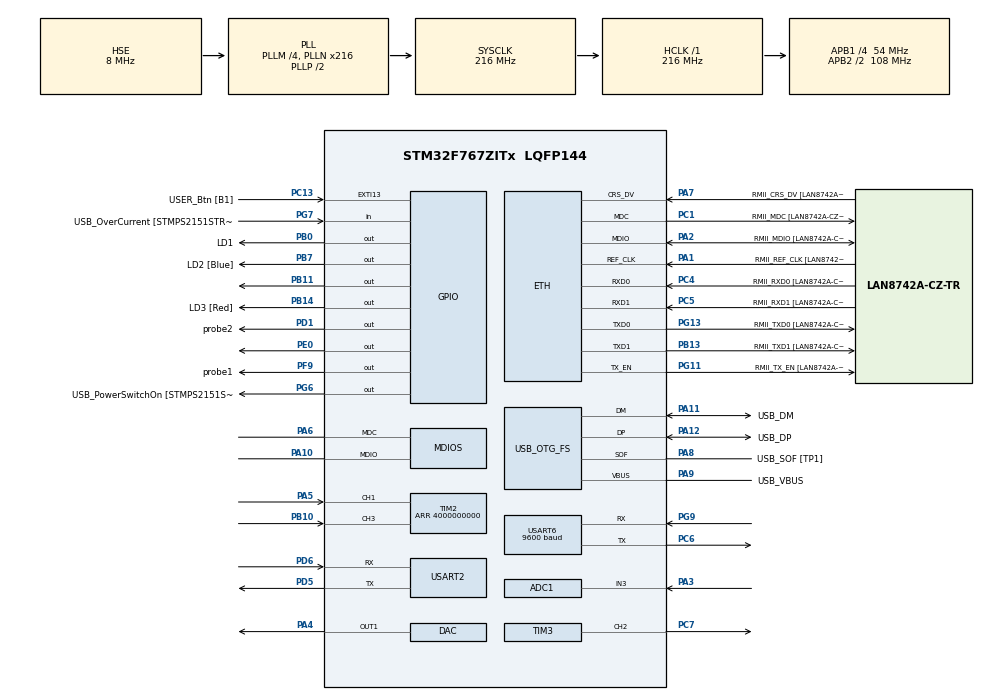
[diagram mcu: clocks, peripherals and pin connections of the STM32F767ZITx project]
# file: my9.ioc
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ADC1.Channel-6\#ChannelRegularConversion=ADC_CHANNEL_3
ADC1.ClockPrescaler=ADC_CLOCK_SYNC_PCLK_DIV4
ADC1.ContinuousConvMode=ENABLE
ADC1.DMAAccessMode=ADC_DMAACCESSMODE_2
ADC1.DMAContinuousRequests=ENABLE
ADC1.DataAlign=ADC_DATAALIGN_RIGHT
ADC1.DiscontinuousConvMode=DISABLE
ADC1.EOCSelection=ADC_EOC_SEQ_CONV
ADC1.EnableAnalogWatchDog=false
ADC1.ExternalTrigConv=ADC_SOFTWARE_START
ADC1.ExternalTrigConvEdge=ADC_EXTERNALTRIGCONVEDGE_NONE
ADC1.InjNumberOfConversion=0
ADC1.Mode=ADC_TRIPLEMODE_INTERL
ADC1.NbrOfConversion=1
ADC1.NbrOfConversionFlag=1
ADC1.Rank-6\#ChannelRegularConversion=1
ADC1.Resolution=ADC_RESOLUTION_12B
ADC1.SamplingTime-6\#ChannelRegularConversion=ADC_SAMPLETIME_3CYCLES
ADC1.ScanConvMode=ADC_SCAN_DISABLE
ADC1.TwoSamplingDelay=ADC_TWOSAMPLINGDELAY_5CYCLES
ADC1.master=1
ADC2.Channel-22\#ChannelRegularConversion=ADC_CHANNEL_3
ADC2.Channel-26\#ChannelRegularConversion=ADC_CHANNEL_3
ADC2.ContinuousConvMode=ENABLE
ADC2.DMAAccessMode=ADC_DMAACCESSMODE_2
ADC2.DMAContinuousRequests=DISABLE
ADC2.DataAlign=ADC_DATAALIGN_RIGHT
ADC2.DiscontinuousConvMode=DISABLE
ADC2.EOCSelection=ADC_EOC_SEQ_CONV
ADC2.EnableAnalogWatchDog=false
ADC2.InjNumberOfConversion=0
ADC2.Mode=ADC_TRIPLEMODE_INTERL
ADC2.NbrOfConversion=1
ADC2.NbrOfConversionFlag=1
ADC2.Rank-22\#ChannelRegularConversion=1
ADC2.Rank-26\#ChannelRegularConversion=1
ADC2.Resolution=ADC_RESOLUTION_12B
ADC2.SamplingTime-22\#ChannelRegularConversion=ADC_SAMPLETIME_3CYCLES
ADC2.SamplingTime-26\#ChannelRegularConversion=ADC_SAMPLETIME_3CYCLES
ADC2.ScanConvMode=ADC_SCAN_DISABLE
ADC3.Channel-14\#ChannelRegularConversion=ADC_CHANNEL_3
ADC3.ContinuousConvMode=ENABLE
ADC3.DMAAccessMode=ADC_DMAACCESSMODE_2
ADC3.DMAContinuousRequests=DISABLE
ADC3.DataAlign=ADC_DATAALIGN_RIGHT
ADC3.DiscontinuousConvMode=DISABLE
ADC3.EOCSelection=ADC_EOC_SEQ_CONV
ADC3.EnableAnalogWatchDog=false
ADC3.InjNumberOfConversion=0
ADC3.Mode=ADC_TRIPLEMODE_INTERL
ADC3.NbrOfConversion=1
ADC3.NbrOfConversionFlag=1
ADC3.Rank-14\#ChannelRegularConversion=1
ADC3.Resolution=ADC_RESOLUTION_12B
ADC3.SamplingTime-14\#ChannelRegularConversion=ADC_SAMPLETIME_3CYCLES
ADC3.ScanConvMode=ADC_SCAN_DISABLE
CORTEX_M7.CPU_DCache=Disabled
CORTEX_M7.CPU_ICache=Enabled
CORTEX_M7.PREFETCH_ENABLE=1
DAC.DAC_Trigger=DAC_TRIGGER_T7_TRGO
Dma.ADC1.2.Direction=DMA_PERIPH_TO_MEMORY
Dma.ADC1.2.FIFOMode=DMA_FIFOMODE_ENABLE
Dma.ADC1.2.FIFOThreshold=DMA_FIFO_THRESHOLD_FULL
Dma.ADC1.2.Instance=DMA2_Stream4
Dma.ADC1.2.MemBurst=DMA_MBURST_INC4
Dma.ADC1.2.MemDataAlignment=DMA_MDATAALIGN_WORD
Dma.ADC1.2.MemInc=DMA_MINC_ENABLE
Dma.ADC1.2.Mode=DMA_CIRCULAR
Dma.ADC1.2.PeriphBurst=DMA_PBURST_SINGLE
Dma.ADC1.2.PeriphDataAlignment=DMA_PDATAALIGN_HALFWORD
Dma.ADC1.2.PeriphInc=DMA_PINC_DISABLE
Dma.ADC1.2.Priority=DMA_PRIORITY_HIGH
Dma.DAC1.1.Direction=DMA_MEMORY_TO_PERIPH
Dma.DAC1.1.FIFOMode=DMA_FIFOMODE_ENABLE
Dma.DAC1.1.FIFOThreshold=DMA_FIFO_THRESHOLD_3QUARTERSFULL
Dma.DAC1.1.Instance=DMA1_Stream5
Dma.DAC1.1.MemBurst=DMA_MBURST_SINGLE
Dma.DAC1.1.MemDataAlignment=DMA_MDATAALIGN_HALFWORD
Dma.DAC1.1.MemInc=DMA_MINC_ENABLE
Dma.DAC1.1.Mode=DMA_CIRCULAR
Dma.DAC1.1.PeriphBurst=DMA_PBURST_INC4
Dma.DAC1.1.PeriphDataAlignment=DMA_PDATAALIGN_HALFWORD
Dma.DAC1.1.PeriphInc=DMA_PINC_DISABLE
Dma.DAC1.1.Priority=DMA_PRIORITY_LOW
Dma.Request0=TIM2_UP/CH3
Dma.Request1=DAC1
Dma.Request2=ADC1
Dma.Request3=USART6_RX
Dma.TIM2_UP/CH3.0.Direction=DMA_PERIPH_TO_MEMORY
Dma.TIM2_UP/CH3.0.FIFOMode=DMA_FIFOMODE_DISABLE
Dma.TIM2_UP/CH3.0.Instance=DMA1_Stream1
Dma.TIM2_UP/CH3.0.MemDataAlignment=DMA_MDATAALIGN_WORD
Dma.TIM2_UP/CH3.0.MemInc=DMA_MINC_ENABLE
Dma.TIM2_UP/CH3.0.Mode=DMA_CIRCULAR
Dma.TIM2_UP/CH3.0.PeriphDataAlignment=DMA_PDATAALIGN_WORD
Dma.TIM2_UP/CH3.0.PeriphInc=DMA_PINC_DISABLE
Dma.TIM2_UP/CH3.0.Priority=DMA_PRIORITY_LOW
Dma.USART6_RX.3.Direction=DMA_PERIPH_TO_MEMORY
Dma.USART6_RX.3.FIFOMode=DMA_FIFOMODE_DISABLE
Dma.USART6_RX.3.Instance=DMA2_Stream1
Dma.USART6_RX.3.MemDataAlignment=DMA_MDATAALIGN_BYTE
Dma.USART6_RX.3.MemInc=DMA_MINC_ENABLE
Dma.USART6_RX.3.Mode=DMA_CIRCULAR
Dma.USART6_RX.3.PeriphDataAlignment=DMA_PDATAALIGN_BYTE
Dma.USART6_RX.3.PeriphInc=DMA_PINC_DISABLE
Dma.USART6_RX.3.Priority=DMA_PRIORITY_MEDIUM
ETH.MACAddr=00\:80\:E1\:00\:AA\:02
ETH.MediaInterface=ETH_MEDIA_INTERFACE_RMII
ETH.PhyAddress=0
FREERTOS.BinarySemaphores01=myBinarySem01,Dynamic,NULL
FREERTOS.INCLUDE_vTaskCleanUpResources=1
FREERTOS.INCLUDE_vTaskDelayUntil=1
FREERTOS.INCLUDE_xQueueGetMutexHolder=1
FREERTOS.INCLUDE_xSemaphoreGetMutexHolder=1
FREERTOS.INCLUDE_xTimerPendFunctionCall=1
FREERTOS.Mutexes01=myMutex01,Dynamic,NULL
FREERTOS.Queues01=myQueue01,256,uint16_t,0,Dynamic,NULL,NULL
FREERTOS.Tasks01=defaultTask,0,1024,StartDefaultTask,Default,NULL,Dynamic,NULL,NULL;LPTask,-2,1024,StarLPTask,Default,NULL,Dynamic,NULL,NULL
FREERTOS.Timers01=myTimer01,Callback01,osTimerPeriodic,Default,NULL,Dynamic,NULL
FREERTOS.configCHECK_FOR_STACK_OVERFLOW=1
FREERTOS.configMINIMAL_STACK_SIZE=0x100
FREERTOS.configTOTAL_HEAP_SIZE=131072
FREERTOS.configUSE_IDLE_HOOK=1
FREERTOS.configUSE_MALLOC_FAILED_HOOK=1
FREERTOS.configUSE_TIMERS=1
LWIP.ARP_QUEUEING=1
LWIP.ARP_QUEUE_LEN=32
LWIP.ARP_TABLE_SIZE=32
LWIP.CHECKSUM_BY_HARDWARE=1
LWIP.CHECKSUM_CHECK_ICMP=0
LWIP.CHECKSUM_CHECK_TCP=0
LWIP.CHECKSUM_GEN_ICMP=0
LWIP.CHECKSUM_GEN_TCP=0
LWIP.HTTPD_USE_CUSTOM_FSDATA=0
LWIP.IP_DEBUG=LWIP_DBG_OFF
LWIP.LWIP_DBG_MIN_LEVEL=LWIP_DBG_LEVEL_ALL
LWIP.LWIP_DISABLE_MEMP_SANITY_CHECKS=0
LWIP.LWIP_DNS=1
LWIP.LWIP_HTTPD=1
LWIP.LWIP_HTTPD_ABORT_ON_CLOSE_MEM_ERROR=1
LWIP.LWIP_HTTPD_CGI_SSI=1
LWIP.LWIP_HTTPD_SSI=1
LWIP.LWIP_HTTPD_SSI_RAW=1
LWIP.LWIP_HTTPD_SUPPORT_11_KEEPALIVE=1
LWIP.LWIP_HTTPD_SUPPORT_EXTSTATUS=1
LWIP.LWIP_HTTPD_SUPPORT_POST=1
LWIP.LWIP_NETIF_LINK_CALLBACK=1
LWIP.LWIP_NETIF_STATUS_CALLBACK=1
LWIP.LWIP_RAW=1
LWIP.LWIP_STATS=0
LWIP.MEMP_DEBUG=LWIP_DBG_OFF
LWIP.MEMP_NUM_TCP_PCB_LISTEN=16
LWIP.MEMP_OVERFLOW_CHECK=2
LWIP.MEMP_SANITY_CHECK=1
LWIP.MEM_DEBUG=LWIP_DBG_OFF
LWIP.MEM_SIZE=12000
LWIP.PBUF_DEBUG=LWIP_DBG_OFF
LWIP.PBUF_POOL_SIZE=32
LWIP.RAW_DEBUG=LWIP_DBG_OFF
LWIP.RECV_BUFSIZE_DEFAULT=20000
LWIP.SYS_DEBUG=LWIP_DBG_OFF
LWIP.UDP_DEBUG=LWIP_DBG_OFF
LWIP.Version=v2.0.3_Cube
Mcu.Family=STM32F7
Mcu.Name=STM32F767ZITx
Mcu.Package=LQFP144
NVIC.ADC_IRQn=true\:6\:0\:true\:true\:true\:3\:true\:true
NVIC.DMA1_Stream1_IRQn=true\:6\:0\:true\:false\:true\:true\:false
NVIC.DMA1_Stream5_IRQn=true\:6\:0\:true\:false\:true\:true\:false
NVIC.DMA2_Stream1_IRQn=true\:6\:0\:true\:false\:true\:true\:false
NVIC.DMA2_Stream4_IRQn=true\:5\:0\:false\:false\:true\:true\:false
NVIC.ETH_IRQn=true\:6\:0\:true\:false\:true\:true\:true
NVIC.EXTI15_10_IRQn=true\:6\:0\:true\:true\:true\:4\:true\:true
NVIC.FPU_IRQn=true\:6\:0\:true\:false\:true\:true\:true
NVIC.MDIOS_IRQn=true\:6\:0\:true\:false\:true\:true\:true
NVIC.OTG_FS_IRQn=true\:6\:0\:true\:false\:true\:true\:true
NVIC.PriorityGroup=NVIC_PRIORITYGROUP_4
NVIC.RCC_IRQn=true\:6\:0\:true\:false\:true\:true\:true
NVIC.TIM2_IRQn=true\:6\:0\:true\:false\:true\:true\:true
NVIC.TIM3_IRQn=true\:6\:0\:true\:false\:true\:true\:true
NVIC.TIM6_DAC_IRQn=true\:6\:0\:true\:false\:true\:true\:true
NVIC.TIM8_BRK_TIM12_IRQn=true\:0\:0\:false\:false\:true\:false\:true
NVIC.TimeBase=TIM8_BRK_TIM12_IRQn
NVIC.TimeBaseIP=TIM12
NVIC.USART2_IRQn=true\:6\:0\:true\:true\:true\:1\:true\:true
NVIC.USART6_IRQn=true\:6\:0\:true\:true\:true\:2\:true\:true
PA1.GPIO_Label=RMII_REF_CLK [LAN8742A-CZ-TR_REFCLK0]
PA1.Mode=RMII
PA1.Signal=ETH_REF_CLK
PA10.Mode=Activate
PA10.Signal=MDIOS_MDIO
PA11.GPIO_Label=USB_DM
PA11.Mode=Device_Only
PA11.Signal=USB_OTG_FS_DM
PA12.GPIO_Label=USB_DP
PA12.Mode=Device_Only
PA12.Signal=USB_OTG_FS_DP
PA13.GPIO_Label=TMS
PA13.Mode=Serial_Wire
PA13.Signal=SYS_JTMS-SWDIO
PA14.GPIO_Label=TCK
PA14.Mode=Serial_Wire
PA14.Signal=SYS_JTCK-SWCLK
PA2.GPIO_Label=RMII_MDIO [LAN8742A-CZ-TR_MDIO]
PA2.Mode=RMII
PA2.Signal=ETH_MDIO
PA3.Signal=ADCx_IN3
PA4.Signal=COMP_DAC1_group
PA5.Signal=S_TIM2_CH1_ETR
PA6.Mode=Activate
PA6.Signal=MDIOS_MDC
PA7.GPIO_Label=RMII_CRS_DV [LAN8742A-CZ-TR_CRS_DV]
PA7.Mode=RMII
PA7.Signal=ETH_CRS_DV
PA8.GPIO_Label=USB_SOF [TP1]
PA8.Mode=Activate_SOF_FS
PA8.Signal=USB_OTG_FS_SOF
PA9.GPIO_Label=USB_VBUS
PA9.Mode=Activate_VBUS
PA9.Signal=USB_OTG_FS_VBUS
PB0.GPIO_Label=LD1
PB0.Signal=GPIO_Output
PB10.Signal=S_TIM2_CH3
PB11.Signal=GPIO_Output
PB13.GPIO_Label=RMII_TXD1 [LAN8742A-CZ-TR_TXD1]
PB13.Mode=RMII
PB13.Signal=ETH_TXD1
PB14.GPIO_Label=LD3 [Red]
PB14.Signal=GPIO_Output
PB3.GPIO_Label=SWO
PB3.Signal=SYS_JTDO-SWO
PB7.GPIO_Label=LD2 [Blue]
PB7.Signal=GPIO_Output
PC1.GPIO_Label=RMII_MDC [LAN8742A-CZ-TR_MDC]
PC1.Mode=RMII
PC1.Signal=ETH_MDC
PC13.GPIO_Label=USER_Btn [B1]
PC13.Signal=GPXTI13
PC14/OSC32_IN.Mode=LSE-External-Oscillator
PC14/OSC32_IN.Signal=RCC_OSC32_IN
PC15/OSC32_OUT.Mode=LSE-External-Oscillator
PC15/OSC32_OUT.Signal=RCC_OSC32_OUT
PC4.GPIO_Label=RMII_RXD0 [LAN8742A-CZ-TR_RXD0]
PC4.Mode=RMII
PC4.Signal=ETH_RXD0
PC5.GPIO_Label=RMII_RXD1 [LAN8742A-CZ-TR_RXD1]
PC5.Mode=RMII
PC5.Signal=ETH_RXD1
PC6.Mode=Asynchronous
PC6.Signal=USART6_TX
PC7.Signal=S_TIM3_CH2
PD1.GPIO_Label=probe2
PD1.GPIO_PuPd=GPIO_PULLUP
PD1.GPIO_Speed=GPIO_SPEED_FREQ_HIGH
PD1.Signal=GPIO_Output
PD5.Mode=Asynchronous
PD5.Signal=USART2_TX
PD6.Mode=Asynchronous
PD6.Signal=USART2_RX
PD8.GPIO_Label=STLK_RX [STM32F103CBT6_PA3]
PD8.Signal=USART3_TX
PD9.GPIO_Label=STLK_TX [STM32F103CBT6_PA2]
PD9.Signal=USART3_RX
PE0.Signal=GPIO_Output
PF9.GPIO_Label=probe1
PF9.GPIO_PuPd=GPIO_PULLUP
PF9.GPIO_Speed=GPIO_SPEED_FREQ_HIGH
PF9.Signal=GPIO_Output
PG11.GPIO_Label=RMII_TX_EN [LAN8742A-CZ-TR_TXEN]
PG11.Mode=RMII
PG11.Signal=ETH_TX_EN
PG13.GPIO_Label=RMII_TXD0 [LAN8742A-CZ-TR_TXD0]
PG13.Mode=RMII
PG13.Signal=ETH_TXD0
PG6.GPIO_Label=USB_PowerSwitchOn [STMPS2151STR_EN]
PG6.Signal=GPIO_Output
PG7.GPIO_Label=USB_OverCurrent [STMPS2151STR_FAULT]
PG7.Signal=GPIO_Input
PG9.GPIO_Mode=GPIO_MODE_AF_PP
PG9.Mode=Asynchronous
PG9.Signal=USART6_RX
PH0/OSC_IN.GPIO_Label=MCO [STM32F103CBT6_PA8]
PH0/OSC_IN.Mode=HSE-External-Oscillator
PH0/OSC_IN.Signal=RCC_OSC_IN
PH1/OSC_OUT.Mode=HSE-External-Oscillator
PH1/OSC_OUT.Signal=RCC_OSC_OUT
ProjectManager.HeapSize=0x40000
ProjectManager.StackSize=0x8000
ProjectManager.TargetToolchain=SW4STM32
RCC.48MHZClocksFreq_Value=24000000
RCC.AHBFreq_Value=216000000
RCC.APB1CLKDivider=RCC_HCLK_DIV4
RCC.APB1Freq_Value=54000000
RCC.APB1TimFreq_Value=108000000
RCC.APB2CLKDivider=RCC_HCLK_DIV2
RCC.APB2Freq_Value=108000000
RCC.APB2TimFreq_Value=216000000
RCC.CortexFreq_Value=216000000
RCC.HCLKFreq_Value=216000000
RCC.HSE_VALUE=8000000
RCC.HSI_VALUE=16000000
RCC.PLL48CLockSelection=RCC_CLK48SOURCE_PLLSAIP
RCC.PLLM=4
RCC.PLLMUL=RCC_PLL_MUL9
RCC.PLLN=216
RCC.PLLQ=6
RCC.PLLSAIP=RCC_PLLSAIP_DIV8
RCC.PRESCALERUSB=RCC_USBCLKSOURCE_PLL_DIV1_5
RCC.SYSCLKFreq_VALUE=216000000
RCC.SYSCLKSource=RCC_SYSCLKSOURCE_PLLCLK
RCC.SYSCLKSourceVirtual=RCC_SYSCLKSOURCE_PLLCLK
RCC.USBFreq_Value=48000000
RCC.VCOOutputFreq_Value=432000000
SH.ADCx_IN3.0=ADC1_IN3,IN3
SH.ADCx_IN3.1=ADC3_IN3,IN3
SH.ADCx_IN3.2=ADC2_IN3,IN3
SH.COMP_DAC1_group.0=DAC_OUT1,DAC_OUT1
SH.S_TIM2_CH1_ETR.0=TIM2_CH1,TriggerSource_TI1FP1
SH.S_TIM2_CH1_ETR.1=TIM2_CH1,Input_Capture1_from_TI1
SH.S_TIM2_CH1_ETR.2=TIM2_CH1,Input_Capture2_from_TI1
SH.S_TIM2_CH3.0=TIM2_CH3,Input_Capture3_from_TI3
SH.S_TIM3_CH2.0=TIM3_CH2,PWM Generation2 CH2
TIM2.AutoReloadPreload=TIM_AUTORELOAD_PRELOAD_DISABLE
TIM2.Channel-Input_Capture1_from_TI1=TIM_CHANNEL_1
TIM2.Channel-Input_Capture2_from_TI1=TIM_CHANNEL_2
TIM2.Channel-Input_Capture3_from_TI3=TIM_CHANNEL_3
TIM2.CounterMode=TIM_COUNTERMODE_UP
TIM2.Period=4000000000
TIM3.AutoReloadPreload=TIM_AUTORELOAD_PRELOAD_ENABLE
TIM3.Channel-PWM\ Generation2\ CH2=TIM_CHANNEL_2
TIM3.Period=10000
TIM3.Prescaler=10800
TIM3.Pulse-PWM\ Generation2\ CH2=10
TIM6.AutoReloadPreload=TIM_AUTORELOAD_PRELOAD_ENABLE
TIM6.Period=10000
TIM6.Prescaler=10800
TIM6.TIM_MasterOutputTrigger=TIM_TRGO_ENABLE
TIM7.AutoReloadPreload=TIM_AUTORELOAD_PRELOAD_ENABLE
TIM7.Period=1100
TIM7.TIM_MasterOutputTrigger=TIM_TRGO_UPDATE
USART2.VirtualMode-Asynchronous=VM_ASYNC
USART2.WordLength=WORDLENGTH_8B
USART6.BaudRate=9600
USART6.DMADisableonRxErrorParam=ADVFEATURE_DMA_DISABLEONRXERROR
USART6.OverrunDisableParam=ADVFEATURE_OVERRUN_DISABLE
USART6.VirtualMode-Asynchronous=VM_ASYNC
USART6.WordLength=WORDLENGTH_8B
USB_DEVICE.CLASS_NAME_FS=CDC
USB_DEVICE.VirtualMode-CDC_FS=Cdc
USB_DEVICE.VirtualModeFS=Cdc_FS
USB_OTG_FS.VirtualMode=Device_Only
VP_CRC_VS_CRC.Mode=CRC_Activate
VP_FATFS_VS_Generic.Mode=User_defined
VP_FREERTOS_VS_ENABLE.Mode=Enabled
VP_LWIP_VS_Enabled.Mode=Enabled
VP_MBEDTLS_VS_MBEDTLS.Mode=Enabled
VP_RNG_VS_RNG.Mode=RNG_Activate
VP_SYS_VS_tim12.Mode=TIM12
VP_TIM1_VS_ClockSourceINT.Mode=Internal
VP_TIM2_VS_ClockSourceINT.Mode=Internal
VP_TIM2_VS_ControllerModeReset.Mode=Reset Mode
VP_TIM3_VS_ClockSourceINT.Mode=Internal
VP_TIM6_VS_ClockSourceINT.Mode=Enable_Timer
VP_TIM7_VS_ClockSourceINT.Mode=Enable_Timer
VP_USB_DEVICE_VS_USB_DEVICE_CDC_FS.Mode=CDC_FS
board=NUCLEO-F767ZI

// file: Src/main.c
/**
  ******************************************************************************
  * @file           : main.c
  * @brief          : Main program body
  ******************************************************************************
  * This notice applies to any and all portions of this file
  * that are not between comment pairs USER CODE BEGIN and
  * USER CODE END. Other portions of this file, whether
  * inserted by the user or by software development tools
  * are owned by their respective copyright owners.
  *
  * Copyright (c) 2018 STMicroelectronics International N.V.
  * All rights reserved.
  *
  * Redistribution and use in source and binary forms, with or without
  * modification, are permitted, provided that the following conditions are met:
  *
  * 1. Redistribution of source code must retain the above copyright notice,
  *    this list of conditions and the following disclaimer.
  * 2. Redistributions in binary form must reproduce the above copyright notice,
  *    this list of conditions and the following disclaimer in the documentation
  *    and/or other materials provided with the distribution.
  * 3. Neither the name of STMicroelectronics nor the names of other
  *    contributors to this software may be used to endorse or promote products
  *    derived from this software without specific written permission.
  * 4. This software, including modifications and/or derivative works of this
  *    software, must execute solely and exclusively on microcontroller or
  *    microprocessor devices manufactured by or for STMicroelectronics.
  * 5. Redistribution and use of this software other than as permitted under
  *    this license is void and will automatically terminate your rights under
  *    this license.
  *
  * THIS SOFTWARE IS PROVIDED BY STMICROELECTRONICS AND CONTRIBUTORS "AS IS"
  * AND ANY EXPRESS, IMPLIED OR STATUTORY WARRANTIES, INCLUDING, BUT NOT
  * LIMITED TO, THE IMPLIED WARRANTIES OF MERCHANTABILITY, FITNESS FOR A
  * PARTICULAR PURPOSE AND NON-INFRINGEMENT OF THIRD PARTY INTELLECTUAL PROPERTY
  * RIGHTS ARE DISCLAIMED TO THE FULLEST EXTENT PERMITTED BY LAW. IN NO EVENT
  * SHALL STMICROELECTRONICS OR CONTRIBUTORS BE LIABLE FOR ANY DIRECT, INDIRECT,
  * INCIDENTAL, SPECIAL, EXEMPLARY, OR CONSEQUENTIAL DAMAGES (INCLUDING, BUT NOT
  * LIMITED TO, PROCUREMENT OF SUBSTITUTE GOODS OR SERVICES; LOSS OF USE, DATA,
  * OR PROFITS; OR BUSINESS INTERRUPTION) HOWEVER CAUSED AND ON ANY THEORY OF
  * LIABILITY, WHETHER IN CONTRACT, STRICT LIABILITY, OR TORT (INCLUDING
  * NEGLIGENCE OR OTHERWISE) ARISING IN ANY WAY OUT OF THE USE OF THIS SOFTWARE,
  * EVEN IF ADVISED OF THE POSSIBILITY OF SUCH DAMAGE.
  *
  ******************************************************************************
  */
#include "main.h"
#include "stm32f7xx_hal.h"
#include "cmsis_os.h"
#include "fatfs.h"
#include "mbedtls.h"
#include "usb_device.h"

/* USER CODE BEGIN Includes */
#include <time.h>
#include <stdlib.h>
#include <stdio.h>
#include "netif.h"
#include "adcstream.h"
#include "neo7m.h"
#include "mydebug.h"
#include "ip4.h"
#include "lwipopts.h"
#include "lwip/prot/dhcp.h"

#include "udpstream.h"
#include "version.h"
#include "www.h"
#include "dhcp.h"
//#define netif_dhcp_data(netif) ((struct dhcp*)netif_get_client_data(netif, LWIP_NETIF_CLIENT_DATA_INDEX_DHCP))
/* USER CODE END Includes */

ADC_HandleTypeDef hadc1;
ADC_HandleTypeDef hadc2;
ADC_HandleTypeDef hadc3;
DMA_HandleTypeDef hdma_adc1;

CRC_HandleTypeDef hcrc;

DAC_HandleTypeDef hdac;
DMA_HandleTypeDef hdma_dac1;

MDIOS_HandleTypeDef hmdios;

RNG_HandleTypeDef hrng;

TIM_HandleTypeDef htim1;
TIM_HandleTypeDef htim2;
TIM_HandleTypeDef htim3;
TIM_HandleTypeDef htim6;
TIM_HandleTypeDef htim7;
DMA_HandleTypeDef hdma_tim2_up_ch3;

UART_HandleTypeDef huart2;
UART_HandleTypeDef huart6;
DMA_HandleTypeDef hdma_usart6_rx;

osThreadId defaultTaskHandle;
osThreadId LPTaskHandle;
osMessageQId myQueue01Handle;
osTimerId myTimer01Handle;
osMutexId myMutex01Handle;
osSemaphoreId myBinarySem01Handle;

/* USER CODE BEGIN PV */
/* Private variables ---------------------------------------------------------*/
struct netif *netif, *netif2;
extern const ip4_addr_t *ipaddr;
uint32_t t1sec = 0;
extern uint32_t t2cap[1];
/* USER CODE END PV */

void SystemClock_Config(void);
static void MX_GPIO_Init(void);
static void MX_DMA_Init(void);
static void MX_MDIOS_Init(void);
static void MX_USART2_UART_Init(void);
static void MX_ADC1_Init(void);
static void MX_ADC2_Init(void);
static void MX_ADC3_Init(void);
static void MX_RNG_Init(void);
static void MX_TIM6_Init(void);
static void MX_TIM3_Init(void);
static void MX_TIM7_Init(void);
static void MX_TIM1_Init(void);
static void MX_CRC_Init(void);
static void MX_TIM2_Init(void);
static void MX_USART6_UART_Init(void);
static void MX_DAC_Init(void);
void StartDefaultTask(void const * argument);
void StarLPTask(void const * argument);
void Callback01(void const * argument);
static void MX_NVIC_Init(void);

void HAL_TIM_MspPostInit(TIM_HandleTypeDef *htim);

/* USER CODE BEGIN PFP */
/* Private function prototypes -----------------------------------------------*/

/* USER CODE END PFP */

int main(void)
{

  /* Enable I-Cache-------------------------------------------------------------*/
  SCB_EnableICache();

  /* MCU Configuration----------------------------------------------------------*/

  /* Reset of all peripherals, Initializes the Flash interface and the Systick. */
  HAL_Init();

  /* Configure the system clock */
  SystemClock_Config();

  /* Initialize all configured peripherals */
  MX_GPIO_Init();
  MX_DMA_Init();
  MX_MDIOS_Init();
  MX_USART2_UART_Init();
  MX_ADC1_Init();
  MX_ADC2_Init();
  MX_ADC3_Init();
  MX_RNG_Init();
  MX_TIM6_Init();
  MX_TIM3_Init();
  MX_TIM7_Init();
  MX_TIM1_Init();
  MX_CRC_Init();
  MX_TIM2_Init();
  MX_USART6_UART_Init();
  MX_DAC_Init();

  /* Initialize interrupts */
  MX_NVIC_Init();

  /* Create the mutex(es) */
  /* definition and creation of myMutex01 */
  osMutexDef(myMutex01);
  myMutex01Handle = osMutexCreate(osMutex(myMutex01));

  /* Create the semaphores(s) */
  /* definition and creation of myBinarySem01 */
  osSemaphoreDef(myBinarySem01);
  myBinarySem01Handle = osSemaphoreCreate(osSemaphore(myBinarySem01), 1);

  /* Create the timer(s) */
  /* definition and creation of myTimer01 */
  osTimerDef(myTimer01, Callback01);
  myTimer01Handle = osTimerCreate(osTimer(myTimer01), osTimerPeriodic, NULL);

  /* Create the thread(s) */
  /* definition and creation of defaultTask */
  osThreadDef(defaultTask, StartDefaultTask, osPriorityNormal, 0, 1024);
  defaultTaskHandle = osThreadCreate(osThread(defaultTask), NULL);

  /* definition and creation of LPTask */
  osThreadDef(LPTask, StarLPTask, osPriorityLow, 0, 1024);
  LPTaskHandle = osThreadCreate(osThread(LPTask), NULL);

  /* Create the queue(s) */
  /* definition and creation of myQueue01 */
/* what about the sizeof here??? cd native code */
  osMessageQDef(myQueue01, 256, uint16_t);
  myQueue01Handle = osMessageCreate(osMessageQ(myQueue01), NULL);

  /* Start scheduler */
  osKernelStart();

  /* We should never get here as control is now taken by the scheduler */

  /* Infinite loop */
	while (1) {

	}

}

void SystemClock_Config(void)
{

  RCC_OscInitTypeDef RCC_OscInitStruct;
  RCC_ClkInitTypeDef RCC_ClkInitStruct;
  RCC_PeriphCLKInitTypeDef PeriphClkInitStruct;

    /**Configure the main internal regulator output voltage
    */
  __HAL_RCC_PWR_CLK_ENABLE();

  __HAL_PWR_VOLTAGESCALING_CONFIG(PWR_REGULATOR_VOLTAGE_SCALE1);

    /**Initializes the CPU, AHB and APB busses clocks
    */
  RCC_OscInitStruct.OscillatorType = RCC_OSCILLATORTYPE_HSE;
  RCC_OscInitStruct.HSEState = RCC_HSE_ON;
  RCC_OscInitStruct.PLL.PLLState = RCC_PLL_ON;
  RCC_OscInitStruct.PLL.PLLSource = RCC_PLLSOURCE_HSE;
  RCC_OscInitStruct.PLL.PLLM = 4;
  RCC_OscInitStruct.PLL.PLLN = 216;
  RCC_OscInitStruct.PLL.PLLP = RCC_PLLP_DIV2;
  RCC_OscInitStruct.PLL.PLLQ = 6;
  if (HAL_RCC_OscConfig(&RCC_OscInitStruct) != HAL_OK)
  {
    _Error_Handler(__FILE__, __LINE__);
  }

    /**Activate the Over-Drive mode
    */
  if (HAL_PWREx_EnableOverDrive() != HAL_OK)
  {
    _Error_Handler(__FILE__, __LINE__);
  }

    /**Initializes the CPU, AHB and APB busses clocks
    */
  RCC_ClkInitStruct.ClockType = RCC_CLOCKTYPE_HCLK|RCC_CLOCKTYPE_SYSCLK
                              |RCC_CLOCKTYPE_PCLK1|RCC_CLOCKTYPE_PCLK2;
  RCC_ClkInitStruct.SYSCLKSource = RCC_SYSCLKSOURCE_PLLCLK;
  RCC_ClkInitStruct.AHBCLKDivider = RCC_SYSCLK_DIV1;
  RCC_ClkInitStruct.APB1CLKDivider = RCC_HCLK_DIV4;
  RCC_ClkInitStruct.APB2CLKDivider = RCC_HCLK_DIV2;

  if (HAL_RCC_ClockConfig(&RCC_ClkInitStruct, FLASH_LATENCY_7) != HAL_OK)
  {
    _Error_Handler(__FILE__, __LINE__);
  }

  PeriphClkInitStruct.PeriphClockSelection = RCC_PERIPHCLK_USART2|RCC_PERIPHCLK_USART6
                              |RCC_PERIPHCLK_CLK48;
  PeriphClkInitStruct.PLLSAI.PLLSAIN = 192;
  PeriphClkInitStruct.PLLSAI.PLLSAIR = 2;
  PeriphClkInitStruct.PLLSAI.PLLSAIQ = 2;
  PeriphClkInitStruct.PLLSAI.PLLSAIP = RCC_PLLSAIP_DIV8;
  PeriphClkInitStruct.PLLSAIDivQ = 1;
  PeriphClkInitStruct.PLLSAIDivR = RCC_PLLSAIDIVR_2;
  PeriphClkInitStruct.Usart2ClockSelection = RCC_USART2CLKSOURCE_PCLK1;
  PeriphClkInitStruct.Usart6ClockSelection = RCC_USART6CLKSOURCE_PCLK2;
  PeriphClkInitStruct.Clk48ClockSelection = RCC_CLK48SOURCE_PLLSAIP;
  if (HAL_RCCEx_PeriphCLKConfig(&PeriphClkInitStruct) != HAL_OK)
  {
    _Error_Handler(__FILE__, __LINE__);
  }

    /**Configure the Systick interrupt time
    */
  HAL_SYSTICK_Config(HAL_RCC_GetHCLKFreq()/1000);

    /**Configure the Systick
    */
  HAL_SYSTICK_CLKSourceConfig(SYSTICK_CLKSOURCE_HCLK);

  /* SysTick_IRQn interrupt configuration */
  HAL_NVIC_SetPriority(SysTick_IRQn, 15, 0);
}

/**
  * @brief NVIC Configuration.
  * @retval None
  */
static void MX_NVIC_Init(void)
{
  /* USART2_IRQn interrupt configuration */
  HAL_NVIC_SetPriority(USART2_IRQn, 6, 0);
  HAL_NVIC_EnableIRQ(USART2_IRQn);
  /* USART6_IRQn interrupt configuration */
  HAL_NVIC_SetPriority(USART6_IRQn, 6, 0);
  HAL_NVIC_EnableIRQ(USART6_IRQn);
  /* ADC_IRQn interrupt configuration */
  HAL_NVIC_SetPriority(ADC_IRQn, 6, 0);
  HAL_NVIC_EnableIRQ(ADC_IRQn);
  /* EXTI15_10_IRQn interrupt configuration */
  HAL_NVIC_SetPriority(EXTI15_10_IRQn, 6, 0);
  HAL_NVIC_EnableIRQ(EXTI15_10_IRQn);
}

/* ADC1 init function */
static void MX_ADC1_Init(void)
{

  ADC_MultiModeTypeDef multimode;
  ADC_ChannelConfTypeDef sConfig;

    /**Configure the global features of the ADC (Clock, Resolution, Data Alignment and number of conversion)
    */
  hadc1.Instance = ADC1;
  hadc1.Init.ClockPrescaler = ADC_CLOCK_SYNC_PCLK_DIV4;
  hadc1.Init.Resolution = ADC_RESOLUTION_12B;
  hadc1.Init.ScanConvMode = ADC_SCAN_DISABLE;
  hadc1.Init.ContinuousConvMode = ENABLE;
  hadc1.Init.DiscontinuousConvMode = DISABLE;
  hadc1.Init.ExternalTrigConvEdge = ADC_EXTERNALTRIGCONVEDGE_NONE;
  hadc1.Init.ExternalTrigConv = ADC_SOFTWARE_START;
  hadc1.Init.DataAlign = ADC_DATAALIGN_RIGHT;
  hadc1.Init.NbrOfConversion = 1;
  hadc1.Init.DMAContinuousRequests = ENABLE;
  hadc1.Init.EOCSelection = ADC_EOC_SEQ_CONV;
  if (HAL_ADC_Init(&hadc1) != HAL_OK)
  {
    _Error_Handler(__FILE__, __LINE__);
  }

    /**Configure the ADC multi-mode
    */
  multimode.Mode = ADC_TRIPLEMODE_INTERL;
  multimode.DMAAccessMode = ADC_DMAACCESSMODE_2;
  multimode.TwoSamplingDelay = ADC_TWOSAMPLINGDELAY_5CYCLES;
  if (HAL_ADCEx_MultiModeConfigChannel(&hadc1, &multimode) != HAL_OK)
  {
    _Error_Handler(__FILE__, __LINE__);
  }

    /**Configure for the selected ADC regular channel its corresponding rank in the sequencer and its sample time.
    */
  sConfig.Channel = ADC_CHANNEL_3;
  sConfig.Rank = ADC_REGULAR_RANK_1;
  sConfig.SamplingTime = ADC_SAMPLETIME_3CYCLES;
  if (HAL_ADC_ConfigChannel(&hadc1, &sConfig) != HAL_OK)
  {
    _Error_Handler(__FILE__, __LINE__);
  }

}

/* ADC2 init function */
static void MX_ADC2_Init(void)
{

  ADC_ChannelConfTypeDef sConfig;

    /**Configure the global features of the ADC (Clock, Resolution, Data Alignment and number of conversion)
    */
  hadc2.Instance = ADC2;
  hadc2.Init.ClockPrescaler = ADC_CLOCK_SYNC_PCLK_DIV4;
  hadc2.Init.Resolution = ADC_RESOLUTION_12B;
  hadc2.Init.ScanConvMode = ADC_SCAN_DISABLE;
  hadc2.Init.ContinuousConvMode = ENABLE;
  hadc2.Init.DiscontinuousConvMode = DISABLE;
  hadc2.Init.DataAlign = ADC_DATAALIGN_RIGHT;
  hadc2.Init.NbrOfConversion = 1;
  hadc2.Init.DMAContinuousRequests = DISABLE;
  hadc2.Init.EOCSelection = ADC_EOC_SEQ_CONV;
  if (HAL_ADC_Init(&hadc2) != HAL_OK)
  {
    _Error_Handler(__FILE__, __LINE__);
  }

    /**Configure for the selected ADC regular channel its corresponding rank in the sequencer and its sample time.
    */
  sConfig.Channel = ADC_CHANNEL_3;
  sConfig.Rank = ADC_REGULAR_RANK_1;
  sConfig.SamplingTime = ADC_SAMPLETIME_3CYCLES;
  if (HAL_ADC_ConfigChannel(&hadc2, &sConfig) != HAL_OK)
  {
    _Error_Handler(__FILE__, __LINE__);
  }

}

/* ADC3 init function */
static void MX_ADC3_Init(void)
{

  ADC_ChannelConfTypeDef sConfig;

    /**Configure the global features of the ADC (Clock, Resolution, Data Alignment and number of conversion)
    */
  hadc3.Instance = ADC3;
  hadc3.Init.ClockPrescaler = ADC_CLOCK_SYNC_PCLK_DIV4;
  hadc3.Init.Resolution = ADC_RESOLUTION_12B;
  hadc3.Init.ScanConvMode = ADC_SCAN_DISABLE;
  hadc3.Init.ContinuousConvMode = ENABLE;
  hadc3.Init.DiscontinuousConvMode = DISABLE;
  hadc3.Init.DataAlign = ADC_DATAALIGN_RIGHT;
  hadc3.Init.NbrOfConversion = 1;
  hadc3.Init.DMAContinuousRequests = DISABLE;
  hadc3.Init.EOCSelection = ADC_EOC_SEQ_CONV;
  if (HAL_ADC_Init(&hadc3) != HAL_OK)
  {
    _Error_Handler(__FILE__, __LINE__);
  }

    /**Configure for the selected ADC regular channel its corresponding rank in the sequencer and its sample time.
    */
  sConfig.Channel = ADC_CHANNEL_3;
  sConfig.Rank = ADC_REGULAR_RANK_1;
  sConfig.SamplingTime = ADC_SAMPLETIME_3CYCLES;
  if (HAL_ADC_ConfigChannel(&hadc3, &sConfig) != HAL_OK)
  {
    _Error_Handler(__FILE__, __LINE__);
  }

}

/* CRC init function */
static void MX_CRC_Init(void)
{

  hcrc.Instance = CRC;
  hcrc.Init.DefaultPolynomialUse = DEFAULT_POLYNOMIAL_ENABLE;
  hcrc.Init.DefaultInitValueUse = DEFAULT_INIT_VALUE_ENABLE;
  hcrc.Init.InputDataInversionMode = CRC_INPUTDATA_INVERSION_NONE;
  hcrc.Init.OutputDataInversionMode = CRC_OUTPUTDATA_INVERSION_DISABLE;
  hcrc.InputDataFormat = CRC_INPUTDATA_FORMAT_BYTES;
  if (HAL_CRC_Init(&hcrc) != HAL_OK)
  {
    _Error_Handler(__FILE__, __LINE__);
  }

}

/* DAC init function */
static void MX_DAC_Init(void)
{

  DAC_ChannelConfTypeDef sConfig;

    /**DAC Initialization
    */
  hdac.Instance = DAC;
  if (HAL_DAC_Init(&hdac) != HAL_OK)
  {
    _Error_Handler(__FILE__, __LINE__);
  }

    /**DAC channel OUT1 config
    */
  sConfig.DAC_Trigger = DAC_TRIGGER_T7_TRGO;
  sConfig.DAC_OutputBuffer = DAC_OUTPUTBUFFER_ENABLE;
  if (HAL_DAC_ConfigChannel(&hdac, &sConfig, DAC_CHANNEL_1) != HAL_OK)
  {
    _Error_Handler(__FILE__, __LINE__);
  }

}

/* MDIOS init function */
static void MX_MDIOS_Init(void)
{

  hmdios.Instance = MDIOS;
  hmdios.Init.PortAddress = 0;
  hmdios.Init.PreambleCheck = MDIOS_PREAMBLE_CHECK_ENABLE;
  if (HAL_MDIOS_Init(&hmdios) != HAL_OK)
  {
    _Error_Handler(__FILE__, __LINE__);
  }

}

/* RNG init function */
static void MX_RNG_Init(void)
{

  hrng.Instance = RNG;
  if (HAL_RNG_Init(&hrng) != HAL_OK)
  {
    _Error_Handler(__FILE__, __LINE__);
  }

}

/* TIM1 init function */
static void MX_TIM1_Init(void)
{

  TIM_ClockConfigTypeDef sClockSourceConfig;
  TIM_MasterConfigTypeDef sMasterConfig;

  htim1.Instance = TIM1;
  htim1.Init.Prescaler = 0;
  htim1.Init.CounterMode = TIM_COUNTERMODE_UP;
  htim1.Init.Period = 0;
  htim1.Init.ClockDivision = TIM_CLOCKDIVISION_DIV1;
  htim1.Init.RepetitionCounter = 0;
  htim1.Init.AutoReloadPreload = TIM_AUTORELOAD_PRELOAD_DISABLE;
  if (HAL_TIM_Base_Init(&htim1) != HAL_OK)
  {
    _Error_Handler(__FILE__, __LINE__);
  }

  sClockSourceConfig.ClockSource = TIM_CLOCKSOURCE_INTERNAL;
  if (HAL_TIM_ConfigClockSource(&htim1, &sClockSourceConfig) != HAL_OK)
  {
    _Error_Handler(__FILE__, __LINE__);
  }

  sMasterConfig.MasterOutputTrigger = TIM_TRGO_RESET;
  sMasterConfig.MasterOutputTrigger2 = TIM_TRGO2_RESET;
  sMasterConfig.MasterSlaveMode = TIM_MASTERSLAVEMODE_DISABLE;
  if (HAL_TIMEx_MasterConfigSynchronization(&htim1, &sMasterConfig) != HAL_OK)
  {
    _Error_Handler(__FILE__, __LINE__);
  }

}

/* TIM2 init function */
static void MX_TIM2_Init(void)
{

  TIM_ClockConfigTypeDef sClockSourceConfig;
  TIM_SlaveConfigTypeDef sSlaveConfig;
  TIM_MasterConfigTypeDef sMasterConfig;
  TIM_IC_InitTypeDef sConfigIC;

  htim2.Instance = TIM2;
  htim2.Init.Prescaler = 0;
  htim2.Init.CounterMode = TIM_COUNTERMODE_UP;
  htim2.Init.Period = 4000000000;
  htim2.Init.ClockDivision = TIM_CLOCKDIVISION_DIV1;
  htim2.Init.AutoReloadPreload = TIM_AUTORELOAD_PRELOAD_DISABLE;
  if (HAL_TIM_Base_Init(&htim2) != HAL_OK)
  {
    _Error_Handler(__FILE__, __LINE__);
  }

  sClockSourceConfig.ClockSource = TIM_CLOCKSOURCE_INTERNAL;
  if (HAL_TIM_ConfigClockSource(&htim2, &sClockSourceConfig) != HAL_OK)
  {
    _Error_Handler(__FILE__, __LINE__);
  }

  if (HAL_TIM_IC_Init(&htim2) != HAL_OK)
  {
    _Error_Handler(__FILE__, __LINE__);
  }

  sSlaveConfig.SlaveMode = TIM_SLAVEMODE_RESET;
  sSlaveConfig.InputTrigger = TIM_TS_TI1FP1;
  sSlaveConfig.TriggerPolarity = TIM_INPUTCHANNELPOLARITY_RISING;
  sSlaveConfig.TriggerFilter = 0;
  if (HAL_TIM_SlaveConfigSynchronization(&htim2, &sSlaveConfig) != HAL_OK)
  {
    _Error_Handler(__FILE__, __LINE__);
  }

  sMasterConfig.MasterOutputTrigger = TIM_TRGO_RESET;
  sMasterConfig.MasterSlaveMode = TIM_MASTERSLAVEMODE_DISABLE;
  if (HAL_TIMEx_MasterConfigSynchronization(&htim2, &sMasterConfig) != HAL_OK)
  {
    _Error_Handler(__FILE__, __LINE__);
  }

  sConfigIC.ICPolarity = TIM_INPUTCHANNELPOLARITY_RISING;
  sConfigIC.ICSelection = TIM_ICSELECTION_DIRECTTI;
  sConfigIC.ICPrescaler = TIM_ICPSC_DIV1;
  sConfigIC.ICFilter = 0;
  if (HAL_TIM_IC_ConfigChannel(&htim2, &sConfigIC, TIM_CHANNEL_1) != HAL_OK)
  {
    _Error_Handler(__FILE__, __LINE__);
  }

  sConfigIC.ICSelection = TIM_ICSELECTION_INDIRECTTI;
  if (HAL_TIM_IC_ConfigChannel(&htim2, &sConfigIC, TIM_CHANNEL_2) != HAL_OK)
  {
    _Error_Handler(__FILE__, __LINE__);
  }

  sConfigIC.ICSelection = TIM_ICSELECTION_DIRECTTI;
  if (HAL_TIM_IC_ConfigChannel(&htim2, &sConfigIC, TIM_CHANNEL_3) != HAL_OK)
  {
    _Error_Handler(__FILE__, __LINE__);
  }

}

/* TIM3 init function */
static void MX_TIM3_Init(void)
{

  TIM_ClockConfigTypeDef sClockSourceConfig;
  TIM_MasterConfigTypeDef sMasterConfig;
  TIM_OC_InitTypeDef sConfigOC;

  htim3.Instance = TIM3;
  htim3.Init.Prescaler = 10800;
  htim3.Init.CounterMode = TIM_COUNTERMODE_UP;
  htim3.Init.Period = 10000;
  htim3.Init.ClockDivision = TIM_CLOCKDIVISION_DIV1;
  htim3.Init.AutoReloadPreload = TIM_AUTORELOAD_PRELOAD_ENABLE;
  if (HAL_TIM_Base_Init(&htim3) != HAL_OK)
  {
    _Error_Handler(__FILE__, __LINE__);
  }

  sClockSourceConfig.ClockSource = TIM_CLOCKSOURCE_INTERNAL;
  if (HAL_TIM_ConfigClockSource(&htim3, &sClockSourceConfig) != HAL_OK)
  {
    _Error_Handler(__FILE__, __LINE__);
  }

  if (HAL_TIM_PWM_Init(&htim3) != HAL_OK)
  {
    _Error_Handler(__FILE__, __LINE__);
  }

  sMasterConfig.MasterOutputTrigger = TIM_TRGO_RESET;
  sMasterConfig.MasterSlaveMode = TIM_MASTERSLAVEMODE_DISABLE;
  if (HAL_TIMEx_MasterConfigSynchronization(&htim3, &sMasterConfig) != HAL_OK)
  {
    _Error_Handler(__FILE__, __LINE__);
  }

  sConfigOC.OCMode = TIM_OCMODE_PWM1;
  sConfigOC.Pulse = 10;
  sConfigOC.OCPolarity = TIM_OCPOLARITY_HIGH;
  sConfigOC.OCFastMode = TIM_OCFAST_DISABLE;
  if (HAL_TIM_PWM_ConfigChannel(&htim3, &sConfigOC, TIM_CHANNEL_2) != HAL_OK)
  {
    _Error_Handler(__FILE__, __LINE__);
  }

  HAL_TIM_MspPostInit(&htim3);

}

/* TIM6 init function */
static void MX_TIM6_Init(void)
{

  TIM_MasterConfigTypeDef sMasterConfig;

  htim6.Instance = TIM6;
  htim6.Init.Prescaler = 10800;
  htim6.Init.CounterMode = TIM_COUNTERMODE_UP;
  htim6.Init.Period = 10000;
  htim6.Init.AutoReloadPreload = TIM_AUTORELOAD_PRELOAD_ENABLE;
  if (HAL_TIM_Base_Init(&htim6) != HAL_OK)
  {
    _Error_Handler(__FILE__, __LINE__);
  }

  sMasterConfig.MasterOutputTrigger = TIM_TRGO_ENABLE;
  sMasterConfig.MasterSlaveMode = TIM_MASTERSLAVEMODE_DISABLE;
  if (HAL_TIMEx_MasterConfigSynchronization(&htim6, &sMasterConfig) != HAL_OK)
  {
    _Error_Handler(__FILE__, __LINE__);
  }

}

/* TIM7 init function */
static void MX_TIM7_Init(void)
{

  TIM_MasterConfigTypeDef sMasterConfig;

  htim7.Instance = TIM7;
  htim7.Init.Prescaler = 0;
  htim7.Init.CounterMode = TIM_COUNTERMODE_UP;
  htim7.Init.Period = 1100;
  htim7.Init.AutoReloadPreload = TIM_AUTORELOAD_PRELOAD_ENABLE;
  if (HAL_TIM_Base_Init(&htim7) != HAL_OK)
  {
    _Error_Handler(__FILE__, __LINE__);
  }

  sMasterConfig.MasterOutputTrigger = TIM_TRGO_UPDATE;
  sMasterConfig.MasterSlaveMode = TIM_MASTERSLAVEMODE_DISABLE;
  if (HAL_TIMEx_MasterConfigSynchronization(&htim7, &sMasterConfig) != HAL_OK)
  {
    _Error_Handler(__FILE__, __LINE__);
  }

}

/* USART2 init function */
static void MX_USART2_UART_Init(void)
{

  huart2.Instance = USART2;
  huart2.Init.BaudRate = 115200;
  huart2.Init.WordLength = UART_WORDLENGTH_8B;
  huart2.Init.StopBits = UART_STOPBITS_1;
  huart2.Init.Parity = UART_PARITY_NONE;
  huart2.Init.Mode = UART_MODE_TX_RX;
  huart2.Init.HwFlowCtl = UART_HWCONTROL_NONE;
  huart2.Init.OverSampling = UART_OVERSAMPLING_16;
  huart2.Init.OneBitSampling = UART_ONE_BIT_SAMPLE_DISABLE;
  huart2.AdvancedInit.AdvFeatureInit = UART_ADVFEATURE_NO_INIT;
  if (HAL_UART_Init(&huart2) != HAL_OK)
  {
    _Error_Handler(__FILE__, __LINE__);
  }

}

/* USART6 init function */
static void MX_USART6_UART_Init(void)
{

  huart6.Instance = USART6;
  huart6.Init.BaudRate = 9600;
  huart6.Init.WordLength = UART_WORDLENGTH_8B;
  huart6.Init.StopBits = UART_STOPBITS_1;
  huart6.Init.Parity = UART_PARITY_NONE;
  huart6.Init.Mode = UART_MODE_TX_RX;
  huart6.Init.HwFlowCtl = UART_HWCONTROL_NONE;
  huart6.Init.OverSampling = UART_OVERSAMPLING_16;
  huart6.Init.OneBitSampling = UART_ONE_BIT_SAMPLE_DISABLE;
  huart6.AdvancedInit.AdvFeatureInit = UART_ADVFEATURE_RXOVERRUNDISABLE_INIT|UART_ADVFEATURE_DMADISABLEONERROR_INIT;
  huart6.AdvancedInit.OverrunDisable = UART_ADVFEATURE_OVERRUN_DISABLE;
  huart6.AdvancedInit.DMADisableonRxError = UART_ADVFEATURE_DMA_DISABLEONRXERROR;
  if (HAL_UART_Init(&huart6) != HAL_OK)
  {
    _Error_Handler(__FILE__, __LINE__);
  }

}

static void MX_DMA_Init(void)
{
  /* DMA controller clock enable */
  __HAL_RCC_DMA1_CLK_ENABLE();
  __HAL_RCC_DMA2_CLK_ENABLE();

  /* DMA interrupt init */
  /* DMA1_Stream1_IRQn interrupt configuration */
  HAL_NVIC_SetPriority(DMA1_Stream1_IRQn, 6, 0);
  HAL_NVIC_EnableIRQ(DMA1_Stream1_IRQn);
  /* DMA1_Stream5_IRQn interrupt configuration */
  HAL_NVIC_SetPriority(DMA1_Stream5_IRQn, 6, 0);
  HAL_NVIC_EnableIRQ(DMA1_Stream5_IRQn);
  /* DMA2_Stream1_IRQn interrupt configuration */
  HAL_NVIC_SetPriority(DMA2_Stream1_IRQn, 6, 0);
  HAL_NVIC_EnableIRQ(DMA2_Stream1_IRQn);
  /* DMA2_Stream4_IRQn interrupt configuration */
  HAL_NVIC_SetPriority(DMA2_Stream4_IRQn, 5, 0);
  HAL_NVIC_EnableIRQ(DMA2_Stream4_IRQn);

}

/** Configure pins as
        * Analog
        * Input
        * Output
        * EVENT_OUT
        * EXTI
        * Free pins are configured automatically as Analog (this feature is enabled through
        * the Code Generation settings)
     PD8   ------> USART3_TX
     PD9   ------> USART3_RX
*/
static void MX_GPIO_Init(void)
{

  GPIO_InitTypeDef GPIO_InitStruct;

  /* GPIO Ports Clock Enable */
  __HAL_RCC_GPIOE_CLK_ENABLE();
  __HAL_RCC_GPIOC_CLK_ENABLE();
  __HAL_RCC_GPIOF_CLK_ENABLE();
  __HAL_RCC_GPIOH_CLK_ENABLE();
  __HAL_RCC_GPIOA_CLK_ENABLE();
  __HAL_RCC_GPIOB_CLK_ENABLE();
  __HAL_RCC_GPIOG_CLK_ENABLE();
  __HAL_RCC_GPIOD_CLK_ENABLE();

  /*Configure GPIO pin Output Level */
  HAL_GPIO_WritePin(probe1_GPIO_Port, probe1_Pin, GPIO_PIN_RESET);

  /*Configure GPIO pin Output Level */
  HAL_GPIO_WritePin(GPIOB, LD1_Pin|GPIO_PIN_11|LD3_Pin|LD2_Pin, GPIO_PIN_RESET);

  /*Configure GPIO pin Output Level */
  HAL_GPIO_WritePin(USB_PowerSwitchOn_GPIO_Port, USB_PowerSwitchOn_Pin, GPIO_PIN_RESET);

  /*Configure GPIO pin Output Level */
  HAL_GPIO_WritePin(probe2_GPIO_Port, probe2_Pin, GPIO_PIN_RESET);

  /*Configure GPIO pin Output Level */
  HAL_GPIO_WritePin(GPIOE, GPIO_PIN_0, GPIO_PIN_RESET);

  /*Configure GPIO pins : PE2 PE3 PE4 PE5
                           PE6 PE7 PE8 PE9
                           PE10 PE11 PE12 PE13
                           PE14 PE15 PE1 */
  GPIO_InitStruct.Pin = GPIO_PIN_2|GPIO_PIN_3|GPIO_PIN_4|GPIO_PIN_5
                          |GPIO_PIN_6|GPIO_PIN_7|GPIO_PIN_8|GPIO_PIN_9
                          |GPIO_PIN_10|GPIO_PIN_11|GPIO_PIN_12|GPIO_PIN_13
                          |GPIO_PIN_14|GPIO_PIN_15|GPIO_PIN_1;
  GPIO_InitStruct.Mode = GPIO_MODE_ANALOG;
  GPIO_InitStruct.Pull = GPIO_NOPULL;
  HAL_GPIO_Init(GPIOE, &GPIO_InitStruct);

  /*Configure GPIO pin : USER_Btn_Pin */
  GPIO_InitStruct.Pin = USER_Btn_Pin;
  GPIO_InitStruct.Mode = GPIO_MODE_IT_RISING;
  GPIO_InitStruct.Pull = GPIO_NOPULL;
  HAL_GPIO_Init(USER_Btn_GPIO_Port, &GPIO_InitStruct);

  /*Configure GPIO pins : PF0 PF1 PF2 PF3
                           PF4 PF5 PF6 PF7
                           PF8 PF10 PF11 PF12
                           PF13 PF14 PF15 */
  GPIO_InitStruct.Pin = GPIO_PIN_0|GPIO_PIN_1|GPIO_PIN_2|GPIO_PIN_3
                          |GPIO_PIN_4|GPIO_PIN_5|GPIO_PIN_6|GPIO_PIN_7
                          |GPIO_PIN_8|GPIO_PIN_10|GPIO_PIN_11|GPIO_PIN_12
                          |GPIO_PIN_13|GPIO_PIN_14|GPIO_PIN_15;
  GPIO_InitStruct.Mode = GPIO_MODE_ANALOG;
  GPIO_InitStruct.Pull = GPIO_NOPULL;
  HAL_GPIO_Init(GPIOF, &GPIO_InitStruct);

  /*Configure GPIO pin : probe1_Pin */
  GPIO_InitStruct.Pin = probe1_Pin;
  GPIO_InitStruct.Mode = GPIO_MODE_OUTPUT_PP;
  GPIO_InitStruct.Pull = GPIO_PULLUP;
  GPIO_InitStruct.Speed = GPIO_SPEED_FREQ_HIGH;
  HAL_GPIO_Init(probe1_GPIO_Port, &GPIO_InitStruct);

  /*Configure GPIO pins : PC0 PC2 PC3 PC8
                           PC9 PC10 PC11 PC12 */
  GPIO_InitStruct.Pin = GPIO_PIN_0|GPIO_PIN_2|GPIO_PIN_3|GPIO_PIN_8
                          |GPIO_PIN_9|GPIO_PIN_10|GPIO_PIN_11|GPIO_PIN_12;
  GPIO_InitStruct.Mode = GPIO_MODE_ANALOG;
  GPIO_InitStruct.Pull = GPIO_NOPULL;
  HAL_GPIO_Init(GPIOC, &GPIO_InitStruct);

  /*Configure GPIO pins : PA0 PA15 */
  GPIO_InitStruct.Pin = GPIO_PIN_0|GPIO_PIN_15;
  GPIO_InitStruct.Mode = GPIO_MODE_ANALOG;
  GPIO_InitStruct.Pull = GPIO_NOPULL;
  HAL_GPIO_Init(GPIOA, &GPIO_InitStruct);

  /*Configure GPIO pins : LD1_Pin PB11 LD3_Pin LD2_Pin */
  GPIO_InitStruct.Pin = LD1_Pin|GPIO_PIN_11|LD3_Pin|LD2_Pin;
  GPIO_InitStruct.Mode = GPIO_MODE_OUTPUT_PP;
  GPIO_InitStruct.Pull = GPIO_NOPULL;
  GPIO_InitStruct.Speed = GPIO_SPEED_FREQ_LOW;
  HAL_GPIO_Init(GPIOB, &GPIO_InitStruct);

  /*Configure GPIO pins : PB1 PB2 PB12 PB15
                           PB4 PB5 PB6 PB8
                           PB9 */
  GPIO_InitStruct.Pin = GPIO_PIN_1|GPIO_PIN_2|GPIO_PIN_12|GPIO_PIN_15
                          |GPIO_PIN_4|GPIO_PIN_5|GPIO_PIN_6|GPIO_PIN_8
                          |GPIO_PIN_9;
  GPIO_InitStruct.Mode = GPIO_MODE_ANALOG;
  GPIO_InitStruct.Pull = GPIO_NOPULL;
  HAL_GPIO_Init(GPIOB, &GPIO_InitStruct);

  /*Configure GPIO pins : PG0 PG1 PG2 PG3
                           PG4 PG5 PG8 PG10
                           PG12 PG14 PG15 */
  GPIO_InitStruct.Pin = GPIO_PIN_0|GPIO_PIN_1|GPIO_PIN_2|GPIO_PIN_3
                          |GPIO_PIN_4|GPIO_PIN_5|GPIO_PIN_8|GPIO_PIN_10
                          |GPIO_PIN_12|GPIO_PIN_14|GPIO_PIN_15;
  GPIO_InitStruct.Mode = GPIO_MODE_ANALOG;
  GPIO_InitStruct.Pull = GPIO_NOPULL;
  HAL_GPIO_Init(GPIOG, &GPIO_InitStruct);

  /*Configure GPIO pins : STLK_RX_Pin STLK_TX_Pin */
  GPIO_InitStruct.Pin = STLK_RX_Pin|STLK_TX_Pin;
  GPIO_InitStruct.Mode = GPIO_MODE_AF_PP;
  GPIO_InitStruct.Pull = GPIO_NOPULL;
  GPIO_InitStruct.Speed = GPIO_SPEED_FREQ_VERY_HIGH;
  GPIO_InitStruct.Alternate = GPIO_AF7_USART3;
  HAL_GPIO_Init(GPIOD, &GPIO_InitStruct);

  /*Configure GPIO pins : PD10 PD11 PD12 PD13
                           PD14 PD15 PD0 PD2
                           PD3 PD4 PD7 */
  GPIO_InitStruct.Pin = GPIO_PIN_10|GPIO_PIN_11|GPIO_PIN_12|GPIO_PIN_13
                          |GPIO_PIN_14|GPIO_PIN_15|GPIO_PIN_0|GPIO_PIN_2
                          |GPIO_PIN_3|GPIO_PIN_4|GPIO_PIN_7;
  GPIO_InitStruct.Mode = GPIO_MODE_ANALOG;
  GPIO_InitStruct.Pull = GPIO_NOPULL;
  HAL_GPIO_Init(GPIOD, &GPIO_InitStruct);

  /*Configure GPIO pin : USB_PowerSwitchOn_Pin */
  GPIO_InitStruct.Pin = USB_PowerSwitchOn_Pin;
  GPIO_InitStruct.Mode = GPIO_MODE_OUTPUT_PP;
  GPIO_InitStruct.Pull = GPIO_NOPULL;
  GPIO_InitStruct.Speed = GPIO_SPEED_FREQ_LOW;
  HAL_GPIO_Init(USB_PowerSwitchOn_GPIO_Port, &GPIO_InitStruct);

  /*Configure GPIO pin : USB_OverCurrent_Pin */
  GPIO_InitStruct.Pin = USB_OverCurrent_Pin;
  GPIO_InitStruct.Mode = GPIO_MODE_INPUT;
  GPIO_InitStruct.Pull = GPIO_NOPULL;
  HAL_GPIO_Init(USB_OverCurrent_GPIO_Port, &GPIO_InitStruct);

  /*Configure GPIO pin : probe2_Pin */
  GPIO_InitStruct.Pin = probe2_Pin;
  GPIO_InitStruct.Mode = GPIO_MODE_OUTPUT_PP;
  GPIO_InitStruct.Pull = GPIO_PULLUP;
  GPIO_InitStruct.Speed = GPIO_SPEED_FREQ_HIGH;
  HAL_GPIO_Init(probe2_GPIO_Port, &GPIO_InitStruct);

  /*Configure GPIO pin : PE0 */
  GPIO_InitStruct.Pin = GPIO_PIN_0;
  GPIO_InitStruct.Mode = GPIO_MODE_OUTPUT_PP;
  GPIO_InitStruct.Pull = GPIO_NOPULL;
  GPIO_InitStruct.Speed = GPIO_SPEED_FREQ_LOW;
  HAL_GPIO_Init(GPIOE, &GPIO_InitStruct);

}

/* USER CODE BEGIN 4 */
void netif_status_callbk_fn(struct netif *netif) {

	printf("netif_status changed\n");
	printf(
			"netif: IP address of '%c%c' set to %"U16_F".%"U16_F".%"U16_F".%"U16_F"\n",
			netif->name[0], netif->name[1], ip4_addr1_16(netif_ip4_addr(netif)),
			ip4_addr2_16(netif_ip4_addr(netif)),
			ip4_addr3_16(netif_ip4_addr(netif)),
			ip4_addr4_16(netif_ip4_addr(netif)));
	/*	printf("netif: Gateway %"U16_F".%"U16_F".%"U16_F".%"U16_F"\n",
	 ip4_addr1_16(netif_ip4_gw(netif)),
	 ip4_addr2_16(netif_ip4_gw(netif)),
	 ip4_addr3_16(netif_ip4_gw(netif)),
	 ip4_addr4_16(netif_ip4_gw(netif)));
	 printf("netif: NetMask %"U16_F".%"U16_F".%"U16_F".%"U16_F"\n",
	 ip4_addr1_16(netif_ip4_netmask(netif)),
	 ip4_addr2_16(netif_ip4_netmask(netif)),
	 ip4_addr3_16(netif_ip4_netmask(netif)),
	 ip4_addr4_16(netif_ip4_netmask(netif)));
	 */
//	netif_set_addr(netif,netif_ip4_addr(netif),netif_ip4_gw(netif),netif_ip4_netmask(netif));
}

void netif_link_callbk_fn(struct netif *netif) {

	if (netif->flags & NETIF_FLAG_LINK_UP) {
		printf("netif_link UP, flags=0x%02x\n", netif->flags);
	} else {
		printf("netif_link DOWN, flags=0x%02x\n", netif->flags);
	}

}

uint32_t movavg(uint32_t new) {
	static uint32_t data[16] =
			{ 0, 0, 0, 0, 0, 0, 0, 0, 0, 0, 0, 0, 0, 0, 0, 0 };
	int i;
	uint32_t sum = 0;

	for (i = 0; i < 15; i++) {
		data[i] = data[i + 1];		// old data is low index
		sum += data[i];
	}
	data[15] = new;		// new data at the end
	sum += new;

	return (sum >> 4);
}

void HAL_TIM_IC_CaptureCallback(TIM_HandleTypeDef *htim) { // every second 1 pps (on external signal)
	uint32_t diff;
	static uint32_t lastcap = 0;

	HAL_GPIO_TogglePin(GPIOB, LD1_Pin);		// green led

	if (htim->Instance == TIM2) {
		rtseconds = (statuspkt.NavPvt.sec + 1) % 60;// assume we get here before serial comms updates gps seconds field
//		statuspkt.epochsecs++;
//		neotime();
#if 0		// clktrim with non-resetting pps counter
		if (lastcap > t2cap[0]) {		// counter wrapped
			diff = 4000000000 /*UINT_MAX*/- lastcap + t2cap[0];
		} else {
			diff = t2cap[0] - lastcap;
		}
#else
		diff = lastcap;
#endif
		statuspkt.clktrim = movavg(diff);
		/*		printf("TIM2 IC Callback CCR3=%08x, [0]%08xu, [1]%08x diff=%u, clktrim=%08x",
		 htim->Instance->CCR3, t2cap[0], lastcap, diff, statuspkt.clktrim);
		 printf(" globaladcavg=%u\n",globaladcavg);
		 */
	}
	if (htim->Instance == TIM4) {
		printf("Timer4 callback\n");
	}
	lastcap = t2cap[0];
//	htim->Instance->SR = 0;		// cheat

	/* USER CODE END Callback 1 */
}

void setupnotify() {
	/* Store the handle of the calling task. */
	xTaskToNotify = xTaskGetCurrentTaskHandle();
}

/* USER CODE END 4 */

void StartDefaultTask(void const * argument)
{
  /* init code for USB_DEVICE */
  MX_USB_DEVICE_Init();

  /* MX_LWIP_Init() is generated within mbedtls_net_init() function in net_cockets.c file */
  /* Up to user to call mbedtls_net_init() function in MBEDTLS initialization step */

  /* Up to user define the empty MX_MBEDTLS_Init() function located in mbedtls.c file */
  MX_MBEDTLS_Init();

  /* init code for FATFS */
  MX_FATFS_Init();

  /* USER CODE BEGIN 5 */
	{

		HAL_StatusTypeDef err;
		struct dhcp *dhcp;
		int i, dhcpok = 0;
		uint16_t dacdata[64];

		netif = netif_default;
		netif_set_link_callback(netif, netif_link_callbk_fn);
		netif_set_status_callback(netif, netif_status_callbk_fn);

		t2cap[0] = 44444444;

		statuspkt.uid = MY_UID;		// 16 bits
		statuspkt.majorversion = MAJORVERSION;
		statuspkt.minorversion = MINORVERSION;
		statuspkt.udpcount = 0;
		statuspkt.sysuptime = 0;
		statuspkt.netuptime = 0;
		statuspkt.gpsuptime = 0;

		statuspkt.adcpktssent = 0;

		statuspkt.adctrigoff = TRIG_THRES;

		osDelay(100);

		printf("\n\n--------------------------\nDetector S/N=%d\n", MY_UID);

		printf("STM_UUID=%lx %lx %lx\n", STM32_UUID[0], STM32_UUID[1],STM32_UUID[2]);

#ifdef TESTING
		printf("*** TESTING BUILD USED ***\n");
//		testeeprom();
#endif
		setupneo();
		printf("Neo7 setup returned\n\r");

		HAL_TIM_Base_Start_IT(&htim6);		// basic packet timestamp 32 bits
//		HAL_TIM_Base_Start_IT(&htim3);		// test timebase 1Hz pulse output
//		HAL_TIM_OC_Start_IT(&htim3, TIM_CHANNEL_2);		// 1mS

		TIM_CCxChannelCmd(htim2.Instance, TIM_CHANNEL_1, TIM_CCx_DISABLE);// precision uS timer
		TIM_CCxChannelCmd(htim2.Instance, TIM_CHANNEL_2, TIM_CCx_DISABLE);// precision uS timer
		TIM_CCxChannelCmd(htim2.Instance, TIM_CHANNEL_4, TIM_CCx_DISABLE);// precision uS timer

		HAL_TIM_IC_Stop_DMA(&htim2, TIM_CHANNEL_1);		// precision uS timer
		HAL_TIM_IC_Stop_DMA(&htim2, TIM_CHANNEL_2);		// precision uS timer
		HAL_TIM_IC_Stop_DMA(&htim2, TIM_CHANNEL_4);		// precision uS timer

		//HAL_TIM_IC_Init and HAL_TIM_IC_ConfigChannel
		//  (++) Input Capture :  HAL_TIM_IC_Start(), HAL_TIM_IC_Start_DMA(), HAL_TIM_IC_Start_IT()

		// capture on PB10 input
		if ((err = HAL_TIM_IC_Start_DMA(&htim2, TIM_CHANNEL_3, t2cap,
				(sizeof(t2cap) / 4))) != HAL_OK) {
			printf("TIM_Base_Start_DMA err %i", err);
			_Error_Handler(__FILE__, __LINE__);
		}

		TIM_CCxChannelCmd(htim2.Instance, TIM_CHANNEL_3, TIM_CCx_ENABLE);// capture precision timer

		i = 0;
		dhcp = netif_dhcp_data(netif);		// do not call this too early
		while ((dhcp->state != DHCP_STATE_BOUND) && (i < 10)) {
			printf("Waiting %d for DHCP...\n", i);
			osDelay(2000);
			i++;
		}
		if (i > 10) {
			printf("*****************************************\n");
			printf("************* DHCP ABORTED **************\n");
			printf("*****************************************\n");
			// reboot would be good
		} else {
			dhcpok = 1;
		}
// tim7 drives DAC
#if 1
		for (i = 0; i < sizeof(dacdata) >> 1; i++) {
			dacdata[i] = i * 4096 / (sizeof(dacdata) >> 1);
//			dacdata[i] = 2048;
		}

		HAL_DAC_Start_DMA(&hdac, DAC_CHANNEL_1, dacdata, sizeof(dacdata) >> 1, DAC_ALIGN_12B_R);
		HAL_TIM_Base_Start(&htim7);		// fast interval timer
#endif

		setupnotify();
		startadc();

//		while(1)
//			osDelay(1);
		while (dhcpok) {
			startudp();		// never returns?
		}
	}
  /* USER CODE END 5 */
}

void StarLPTask(void const * argument)
{
  /* USER CODE BEGIN StarLPTask */
	static uint32_t trigs = 0;
	static uint16_t beeptimeout = 0;
	uint32_t reqtimer = 8000;
	uint32_t debugtimer = 0;
	int counter = 0;
	char stmuid[64] = { 0 };

	statuspkt.adcudpover = 0;		// debug use count overruns
	statuspkt.trigcount = 0;		// debug use adc trigger count
	statuspkt.udpsent = 0;	// debug use adc udp sample packet sent count
	osDelay(13000);

	printf("starting httpd\n");
	httpd_init();		// start the www server
// zzz	init_httpd_ssi();	// set up the embedded tag handler
	sprintf(stmuid, "api/Device/%lx%lx%lx", STM32_UUID[0], STM32_UUID[1],STM32_UUID[2]);

	for (;;) {
		tcp_tmr();
		reqtimer++;
		debugtimer++;
		osDelay(1);
		if (statuspkt.trigcount > (3600 + trigs))// spamming: 3600 packets sent in 2 Sec (out of approx 7.2K packets)
				{
			jabber = 2000;		// 2 seconds pause
			statuspkt.jabcnt++;
		} else {
			if (jabber)
				jabber--;		// de-arm count
		}

		if (trigs != statuspkt.trigcount ) {
			HAL_TIM_Base_Start(&htim7);		// fast interval timer
			beeptimeout  = 200;
		} else {
			if (beeptimeout) {
				beeptimeout--;
			} else
				HAL_TIM_Base_Stop(&htim7);		// fast interval timer
		}
		trigs = statuspkt.trigcount;

		if (statuspkt.uid == MY_UID)		// not yet found new S/N from server
		{
			if (reqtimer > 10000) {
				reqtimer = 0;
				printf("Try to get new S/N using http client. Try=%d\n", ++counter);
				httpclient(stmuid);		// zzz testing
				//stats_display() ; // this needs stats in LwIP enabling to do anything
			}

		}
	if (debugtimer > 30000)
	{
		debugtimer = 0;
		stats_display();
		printf("triggers=%04d  ------------------------------------------- %s",trigs,ctime(&epochtime));
	}

	}
  /* USER CODE END StarLPTask */
}

/* Callback01 function */
void Callback01(void const * argument)
{
  /* USER CODE BEGIN Callback01 */
	printf("Callback01\n");
  /* USER CODE END Callback01 */
}

void HAL_TIM_PeriodElapsedCallback(TIM_HandleTypeDef *htim)
{
  /* USER CODE BEGIN Callback 0 */
	if (htim->Instance == TIM2) {
		printf("T2P PeriodElapsedCallback %lu %lu\n", t2cap[0],
				statuspkt.clktrim);
		return;
	}
	if (htim->Instance == TIM3) {
		printf("T3 PeriodElapsedCallback\n");
		return;
	}

	if (htim->Instance == TIM6) { // 1 second (internally timed, not compensated by GPS)
//		printf("T6 PeriodElapsedCallback %u SR=%u\n", myfullcomplete, TIM6->SR);
		t1sec++;
		statuspkt.sysuptime++;
		if (netup)
			statuspkt.netuptime++;
		if (gpslocked) {
			statuspkt.gpsuptime++;
			if (epochvalid == 0) {
				statuspkt.epochsecs = calcepoch();
				epochvalid = 1;
			}
		} else {
			statuspkt.gpsuptime = 0;	// gps uptime is zero
			statuspkt.epochsecs = 0;	// make epoch time obviously wrong
			epochvalid = 0;
		}
		return;
	}

  /* USER CODE END Callback 0 */
  if (htim->Instance == TIM12) {
    HAL_IncTick();
  }
  /* USER CODE BEGIN Callback 1 */
	else {
		printf("Unknown Timer Period Elapsed callback\n");
	}
  /* USER CODE END Callback 1 */
}

void _Error_Handler(char *file, int line)
{
  /* USER CODE BEGIN Error_Handler_Debug */
	/* User can add his own implementation to report the HAL error return state */
	while (1) {
		printf("HAL error\n");
	}
  /* USER CODE END Error_Handler_Debug */
}

/************************ (C) COPYRIGHT STMicroelectronics *****END OF FILE****/

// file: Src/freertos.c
/**
  ******************************************************************************
  * File Name          : freertos.c
  * Description        : Code for freertos applications
  ******************************************************************************
  * This notice applies to any and all portions of this file
  * that are not between comment pairs USER CODE BEGIN and
  * USER CODE END. Other portions of this file, whether
  * inserted by the user or by software development tools
  * are owned by their respective copyright owners.
  *
  * Copyright (c) 2018 STMicroelectronics International N.V.
  * All rights reserved.
  *
  * Redistribution and use in source and binary forms, with or without
  * modification, are permitted, provided that the following conditions are met:
  *
  * 1. Redistribution of source code must retain the above copyright notice,
  *    this list of conditions and the following disclaimer.
  * 2. Redistributions in binary form must reproduce the above copyright notice,
  *    this list of conditions and the following disclaimer in the documentation
  *    and/or other materials provided with the distribution.
  * 3. Neither the name of STMicroelectronics nor the names of other
  *    contributors to this software may be used to endorse or promote products
  *    derived from this software without specific written permission.
  * 4. This software, including modifications and/or derivative works of this
  *    software, must execute solely and exclusively on microcontroller or
  *    microprocessor devices manufactured by or for STMicroelectronics.
  * 5. Redistribution and use of this software other than as permitted under
  *    this license is void and will automatically terminate your rights under
  *    this license.
  *
  * THIS SOFTWARE IS PROVIDED BY STMICROELECTRONICS AND CONTRIBUTORS "AS IS"
  * AND ANY EXPRESS, IMPLIED OR STATUTORY WARRANTIES, INCLUDING, BUT NOT
  * LIMITED TO, THE IMPLIED WARRANTIES OF MERCHANTABILITY, FITNESS FOR A
  * PARTICULAR PURPOSE AND NON-INFRINGEMENT OF THIRD PARTY INTELLECTUAL PROPERTY
  * RIGHTS ARE DISCLAIMED TO THE FULLEST EXTENT PERMITTED BY LAW. IN NO EVENT
  * SHALL STMICROELECTRONICS OR CONTRIBUTORS BE LIABLE FOR ANY DIRECT, INDIRECT,
  * INCIDENTAL, SPECIAL, EXEMPLARY, OR CONSEQUENTIAL DAMAGES (INCLUDING, BUT NOT
  * LIMITED TO, PROCUREMENT OF SUBSTITUTE GOODS OR SERVICES; LOSS OF USE, DATA,
  * OR PROFITS; OR BUSINESS INTERRUPTION) HOWEVER CAUSED AND ON ANY THEORY OF
  * LIABILITY, WHETHER IN CONTRACT, STRICT LIABILITY, OR TORT (INCLUDING
  * NEGLIGENCE OR OTHERWISE) ARISING IN ANY WAY OUT OF THE USE OF THIS SOFTWARE,
  * EVEN IF ADVISED OF THE POSSIBILITY OF SUCH DAMAGE.
  *
  ******************************************************************************
  */

#include "FreeRTOS.h"
#include "task.h"

/* Hook prototypes */
void vApplicationIdleHook(void);
void vApplicationStackOverflowHook(xTaskHandle xTask, signed char *pcTaskName);
void vApplicationMallocFailedHook(void);

/* USER CODE BEGIN 2 */
__weak void vApplicationIdleHook( void )
{
   /* vApplicationIdleHook() will only be called if configUSE_IDLE_HOOK is set
   to 1 in FreeRTOSConfig.h. It will be called on each iteration of the idle
   task. It is essential that code added to this hook function never attempts
   to block in any way (for example, call xQueueReceive() with a block time
   specified, or call vTaskDelay()). If the application makes use of the
   vTaskDelete() API function (as this demo application does) then it is also
   important that vApplicationIdleHook() is permitted to return to its calling
   function, because it is the responsibility of the idle task to clean up
   memory allocated by the kernel to any task that has since been deleted. */
}
/* USER CODE END 2 */

/* USER CODE BEGIN 4 */
__weak void vApplicationStackOverflowHook(xTaskHandle xTask, signed char *pcTaskName)
{
   /* Run time stack overflow checking is performed if
   configCHECK_FOR_STACK_OVERFLOW is defined to 1 or 2. This hook function is
   called if a stack overflow is detected. */
}
/* USER CODE END 4 */

/* USER CODE BEGIN 5 */
__weak void vApplicationMallocFailedHook(void)
{
   /* vApplicationMallocFailedHook() will only be called if
   configUSE_MALLOC_FAILED_HOOK is set to 1 in FreeRTOSConfig.h. It is a hook
   function that will get called if a call to pvPortMalloc() fails.
   pvPortMalloc() is called internally by the kernel whenever a task, queue,
   timer or semaphore is created. It is also called by various parts of the
   demo application. If heap_1.c or heap_2.c are used, then the size of the
   heap available to pvPortMalloc() is defined by configTOTAL_HEAP_SIZE in
   FreeRTOSConfig.h, and the xPortGetFreeHeapSize() API function can be used
   to query the size of free heap space that remains (although it does not
   provide information on how the remaining heap might be fragmented). */
}
/* USER CODE END 5 */

/************************ (C) COPYRIGHT STMicroelectronics *****END OF FILE****/
